# H616 register map
Vendor: Allwinner; Series: H616; File version: 0.1
CPU: other 0, little endian, MPU, no FPU, 0 interrupt priority bits
Registers are 32-bit, read-write, reset 0x0 unless marked. A register's access mark holds for its fields unless they carry their own. Offsets are from the block's base; [hi:lo] are bit positions; 'fields as' and 'values as' point back to an identical list.

## High_Speed_Timer
Base 0x03005000
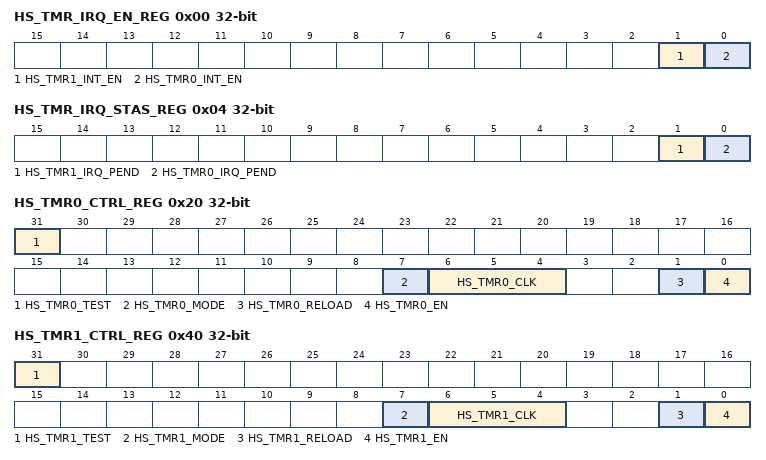
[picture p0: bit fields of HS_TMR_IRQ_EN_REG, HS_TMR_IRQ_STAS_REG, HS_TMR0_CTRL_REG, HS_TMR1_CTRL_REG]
0x00 HS_TMR_IRQ_EN_REG — HS Timer IRQ Enable Register
  [1] HS_TMR1_INT_EN write-1-sets — High Speed Timer 1 Interrupt Enable 0: No effect 1: High Speed Timer1 interval value reached interrupt enable
    0=No_effect; 1=High Speed Timer1 interval value reached interrupt enable
  [0] HS_TMR0_INT_EN write-1-sets — High Speed Timer 0 Interrupt Enable 0: No effect 1: High Speed Timer0 interval value reached interrupt enable
    0=No_effect; 1=High Speed Timer0 interval value reached interrupt enable
0x04 HS_TMR_IRQ_STAS_REG — HS Timer Status Register
  [1] HS_TMR1_IRQ_PEND write-1-clears — High Speed Timer 1 IRQ Pending Setting 1 to the bit will clear it. 0: No effect 1: Pending, High speed timer 1 interval value is reached.
    0=No_effect; 1=Pending, High speed timer 1 interval value is reached
  [0] HS_TMR0_IRQ_PEND write-1-clears — High Speed Timer 0 IRQ Pending Setting 1 to the bit will clear it. 0: No effect 1: Pending, High speed timer 0 interval value is reached.
    0=No_effect; 1=Pending, High speed timer 0 interval value is reached
0x20 HS_TMR0_CTRL_REG — HS Timer 0 Control Register
  [31] HS_TMR0_TEST — High Speed Timer 0 Test Mode In test mode, the low register should be set to 0x1, the high register will down counter. The counter needs to be reloaded. 0: Normal mode 1: Test mode
    0=Normal_mode; 1=Test_mode
  [7] HS_TMR0_MODE — High Speed Timer 0 Mode 0: Continuous mode. When interval value reached, the timer will not disable automatically. 1: Single mode. When interval value reached, the timer will disable automatically.
    0=Continuous mode. When interval value reached, the timer will not disable automatically.; 1=Single mode. When interval value reached, the timer will disable automatically.
  [6:4] HS_TMR0_CLK — Select the pre-scale of the high speed timer 0 clock sources. 000: /1 001: /2 010: /4 011: /8 100: /16 101: / 110: / 111: /
    0=_slash_1 (/1); 1=_slash_2 (/2); 2=_slash_4 (/4); 3=_slash_8 (/8); 4=_slash_16 (/16)
  [1] HS_TMR0_RELOAD write-1-sets — High Speed Timer 0 Reload 0: No effect 1: Reload High Speed Timer 0 Interval Value
    0=No_effect; 1=Reload High Speed Timer 0 Interval Value
  [0] HS_TMR0_EN — High Speed Timer 0 Enable 0: Stop/Pause 1: Start If the timer starts, it will reload the interval value to internal register, and the current counter will count from interval value to 0. If the current counter does not reach the zero, the timer enable bit is set to `0`, the current value counter will pause. At least wait for 2 cycles, the start bit can be set to 1. In timer pause state, the interval value register can be modified. If the timer starts again, and the software hopes the current value register to down-count from the new interval value, the reload bit and the enable bit should be set to 1 at the same time.
    0=Stop_slash_Pause (Stop/Pause); 1=Start If the timer starts, it will reload the interval value to internal register, and the current counter will count from interval value to 0. If the current counter does not reach the zero, the timer enable bit is set to `0`, the current value counter will pause. At least wait for 2 cycles, the start bit can be set to 1. In timer pause state, the interval value register can be modified. If the timer starts again, and the software hopes the current value register to down-count from the new interval value, the reload bit and the enable bit should be set to 1 at the same time.
0x24 HS_TMR0_INTV_LO_REG — HS Timer 0 Interval Value Low Register
  [31:0] HS_TMR0_INTV_VALUE_LO — High Speed Timer 0 Interval Value [31:0]
0x28 HS_TMR0_INTV_HI_REG — HS Timer 0 Interval Value High Register
  [23:0] HS_TMR0_INTV_VALUE_HI — High Speed Timer 0 Interval Value [55:32]
0x2C HS_TMR0_CURNT_LO_REG — HS Timer 0 Current Value Low Register
  [31:0] HS_TMR0_CUR_VALUE_LO — High Speed Timer 0 Current Value [31:0]
0x30 HS_TMR0_CURNT_HI_REG — HS Timer 0 Current Value High Register
  [23:0] HS_TMR0_CUR_VALUE_HI — High Speed Timer 0 Current Value [55:32]
0x40 HS_TMR1_CTRL_REG — HS Timer 1 Control Register
  [31] HS_TMR1_TEST — High Speed Timer 1 Test Mode In test mode, the low register should be set to 0x1, the high register will down counter. The counter needs to be reloaded. 0: Normal mode 1: Test mode
    0=Normal_mode; 1=Test_mode
  [7] HS_TMR1_MODE — High Speed Timer 1 Mode 0: Continuous mode. When interval value reached, the timer will not disable automatically. 1: Single mode. When interval value reached, the timer will disable automatically.
    values as HS_TMR0_CTRL_REG.HS_TMR0_MODE
  [6:4] HS_TMR1_CLK — Select the pre-scale of the high speed timer 1 clock sources. 000: /1 001: /2 010: /4 011: /8 100: /16 101: / 110: / 111: /
    values as HS_TMR0_CTRL_REG.HS_TMR0_CLK
  [1] HS_TMR1_RELOAD write-1-sets — High Speed Timer 1 Reload 0: No effect 1: Reload High Speed Timer 1 Interval Value
    0=No_effect; 1=Reload High Speed Timer 1 Interval Value
  [0] HS_TMR1_EN — High Speed Timer 1 Enable 0: Stop/Pause 1: Start If the timer starts, it will reload the interval value to internal register, and the current counter will count from interval value to 0. If the current counter does not reach the zero, the timer enable bit is set to `0`, the current value counter will pause. At least wait for 2 cycles, the start bit can be set to 1. In timer pause state, the interval value register can be modified. If the timer starts again, and the software hopes the current value register to down-count from the new interval value, the reload bit and the enable bit should be set to 1 at the same time.
    values as HS_TMR0_CTRL_REG.HS_TMR0_EN
0x44 HS_TMR1_INTV_LO_REG — HS Timer 1 Interval Value Low Register
  [31:0] HS_TMR1_INTV_VALUE_LO — High Speed Timer 1 Interval Value [31:0]
0x48 HS_TMR1_INTV_HI_REG — HS Timer 1 Interval Value High Register
  [23:0] HS_TMR1_INTV_VALUE_HI — High Speed Timer 1 Interval Value [55:32]
0x4C HS_TMR1_CURNT_LO_REG — HS Timer 1 Current Value Low Register
  [31:0] HS_TMR1_CUR_VALUE_LO — High Speed Timer 1 Current Value [31:0]
0x50 HS_TMR1_CURNT_HI_REG — HS Timer 1 Current Value High Register
  [23:0] HS_TMR1_CUR_VALUE_HI — High Speed Timer 1 Current Value [55:32]
